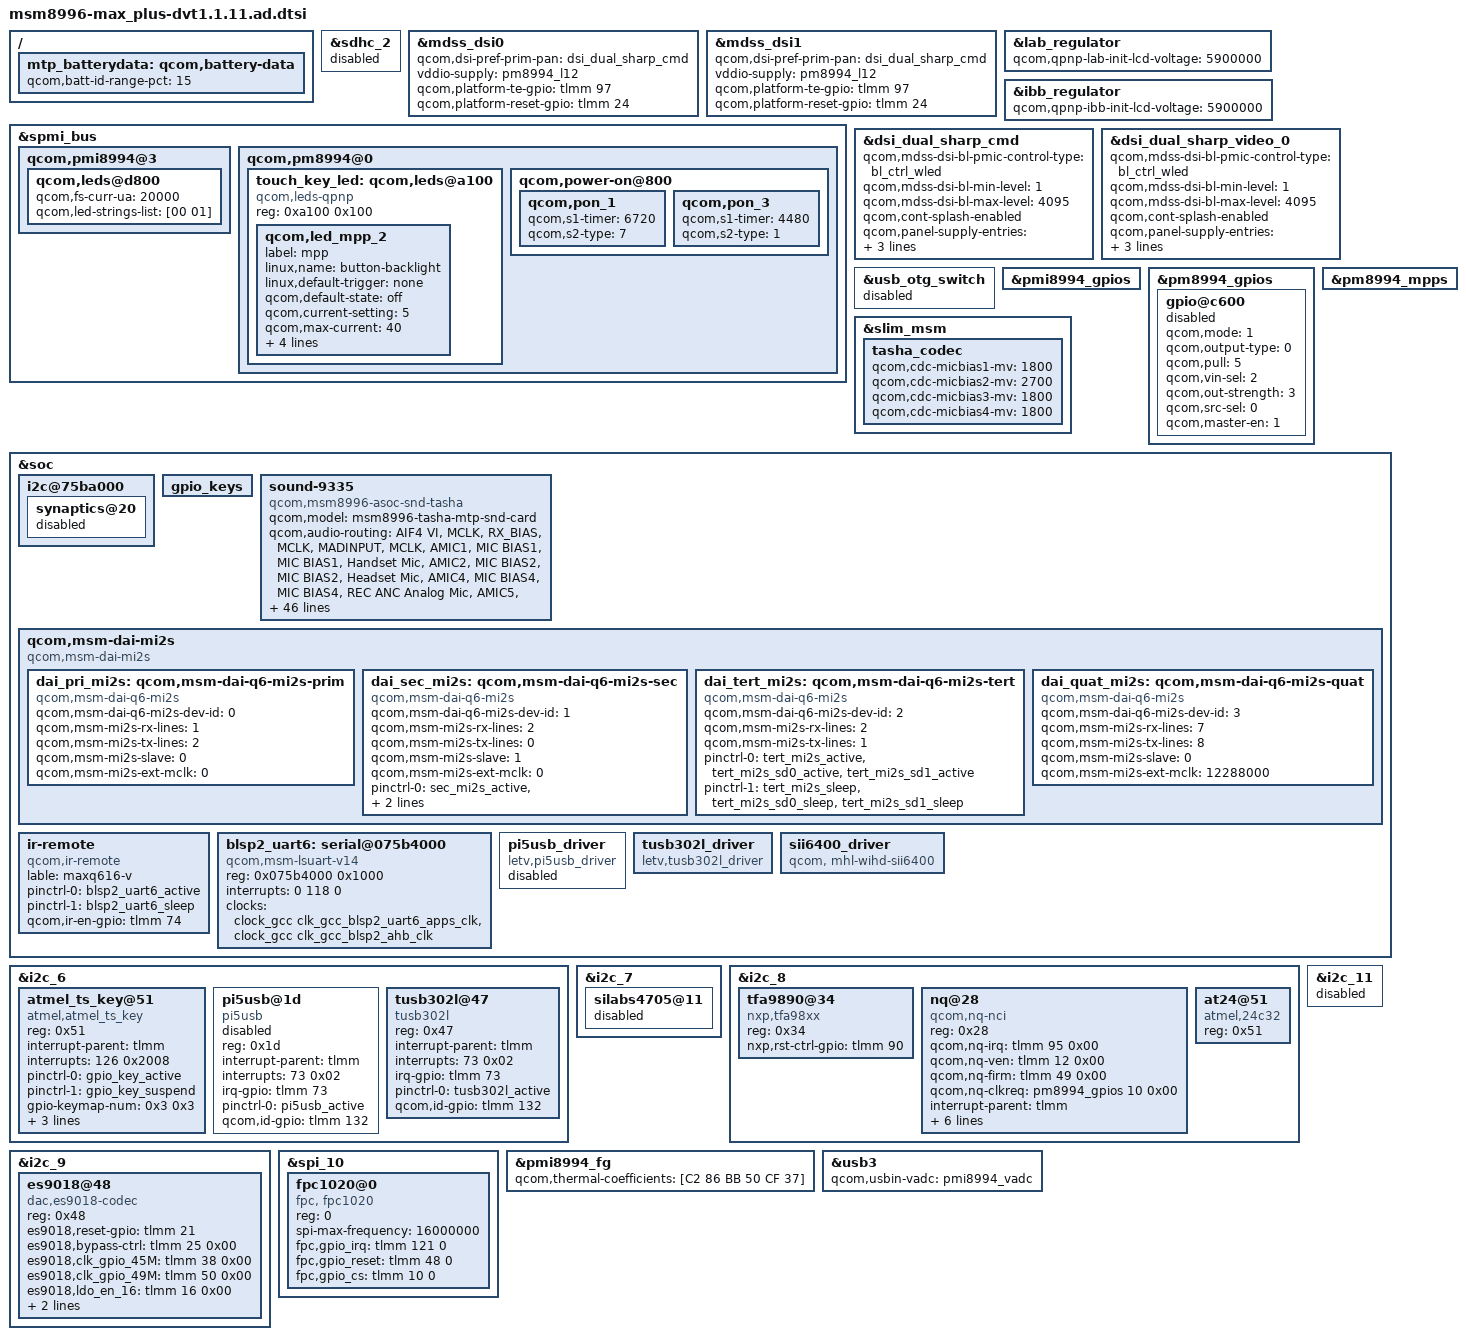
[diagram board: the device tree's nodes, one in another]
/* Copyright (c) 2015, The Linux Foundation. All rights reserved.
 *
 * This program is free software; you can redistribute it and/or modify
 * it under the terms of the GNU General Public License version 2 and
 * only version 2 as published by the Free Software Foundation.
 *
 * This program is distributed in the hope that it will be useful,
 * but WITHOUT ANY WARRANTY; without even the implied warranty of
 * MERCHANTABILITY or FITNESS FOR A PARTICULAR PURPOSE.  See the
 * GNU General Public License for more details.
 */

#include "msm8996-mtp-le-common.dtsi"
#include "msm8996-pinctrl-max_plus.dtsi"
#include "msm8996-le-common.dtsi"
#include "dsi-panel-sharp-dualmipi-cmd.dtsi"
#include "dsi-panel-sharp-dualmipi-video.dtsi"
#include "letv-tp-atmel_mxt_ts.dtsi"
#include "msm8996-camera-sensor-maxplus-dvt1.1.dtsi"

&sdhc_2 {
	status = "disabled";
};

&mdss_dsi0 {
	qcom,dsi-pref-prim-pan = <&dsi_dual_sharp_cmd>;
	vddio-supply = <&pm8994_l12>;
	qcom,platform-te-gpio = <&tlmm 97 0>;
	qcom,platform-reset-gpio = <&tlmm 24 0>;
	/delete-property/ qcom,platform-bklight-en-gpio;
};

&mdss_dsi1 {
	qcom,dsi-pref-prim-pan = <&dsi_dual_sharp_cmd>;
	vddio-supply = <&pm8994_l12>;
	qcom,platform-te-gpio = <&tlmm 97 0>;
	qcom,platform-reset-gpio = <&tlmm 24 0>;
	/delete-property/ qcom,platform-bklight-en-gpio;
};

&lab_regulator {
	qcom,qpnp-lab-init-lcd-voltage = <5900000>;
};

&ibb_regulator {
	qcom,qpnp-ibb-init-lcd-voltage = <5900000>;
};

&spmi_bus {
	qcom,pmi8994@3 {
		qcom,leds@d800 {
			qcom,fs-curr-ua = <20000>;
			qcom,led-strings-list = [00 01];
		};
	};

	qcom,pm8994@0 {
		/* configure pm8994 MPP2 as back-light of touch key */
		touch_key_led: qcom,leds@a100 {
			compatible = "qcom,leds-qpnp";
			reg = <0xa100 0x100>;
			status = "okay";

			qcom,led_mpp_2 {
				label = "mpp";
				linux,name = "button-backlight";
				linux,default-trigger = "none";
				qcom,default-state = "off";
				qcom,current-setting = <5>;
				qcom,max-current = <40>;
				qcom,id = <6>;
				qcom,source-sel = <1>;
				qcom,mode-ctrl = <0x60>; /* current sink mode */
				qcom,mode = "manual";
			};
		};

		/*long press power key hardreset,  long press power+vol_donw into ramdump mode*/
		qcom,power-on@800 {
			qcom,pon_1 {
				qcom,s1-timer = <6720>;
				qcom,s2-type = <7>;
			};

			qcom,pon_3 {
				qcom,s1-timer = <4480>;
				qcom,s2-type = <1>;
			};
		};
	};
};

&dsi_dual_sharp_cmd {
	qcom,mdss-dsi-bl-pmic-control-type = "bl_ctrl_wled";
	qcom,mdss-dsi-bl-min-level = <1>;
	qcom,mdss-dsi-bl-max-level = <4095>;
	qcom,cont-splash-enabled;
	qcom,panel-supply-entries = <&dsi_panel_pwr_supply>;

	qcom,mdss-dsi-panel-timings-phy-v2 = [22 1e 07 08 04 03 04 a0
		22 1e 07 08 04 03 04 a0
		22 1e 07 08 04 03 04 a0
		22 1e 07 08 04 03 04 a0
		23 17 06 08 05 03 04 a0];
};

&dsi_dual_sharp_video_0 {
	qcom,mdss-dsi-bl-pmic-control-type = "bl_ctrl_wled";
	qcom,mdss-dsi-bl-min-level = <1>;
	qcom,mdss-dsi-bl-max-level = <4095>;
	qcom,cont-splash-enabled;
	qcom,panel-supply-entries = <&dsi_panel_pwr_supply>;

	qcom,mdss-dsi-panel-timings-phy-v2 = [22 1e 07 08 04 03 04 a0
		22 1e 07 08 04 03 04 a0
		22 1e 07 08 04 03 04 a0
		22 1e 07 08 04 03 04 a0
		23 17 06 08 05 03 04 a0];
};

&usb_otg_switch {
	status = "disabled";
};

&pmi8994_gpios {
	/delete-node/ gpio@c100; /* PMI8994 GPIO 2 */
	/delete-node/ gpio@c200; /* PMI8994 GPIO 3 */
};

&pm8994_gpios {
	gpio@c600 { /* GPIO 7 - NFC DWL REQ */
		qcom,mode = <1>;
		qcom,output-type = <0>;
		qcom,pull = <5>;
		qcom,vin-sel = <2>;
		qcom,out-strength = <3>;
		qcom,src-sel = <0>;
		qcom,master-en = <1>;
		status = "disabled";
	};
};

&pm8994_mpps {
	/* Remove pm8994 MPP2 reference function, because it is
	configured as back-light of touch key */
	/delete-node/ mpp@a100; /* MPP 2 */
};

&slim_msm {
	tasha_codec {
		qcom,cdc-micbias1-mv = <1800>;
		qcom,cdc-micbias2-mv = <2700>;
		qcom,cdc-micbias3-mv = <1800>;
		qcom,cdc-micbias4-mv = <1800>;

		/delete-node/ wsa881x@20170211;
		/delete-node/ wsa881x@20170212;
		/delete-node/ wsa881x@21170213;
		/delete-node/ wsa881x@21170214;
	};
};

&soc {
	i2c@75ba000 {
		synaptics@20 {
			status = "disabled";
		};
	};

	/delete-node/ gen-vkeys;

	gpio_keys {
		/delete-node/ cam_focus;
	};

	/delete-node/ flash_led;

	sound-9335 {
                compatible = "qcom,msm8996-asoc-snd-tasha";
		qcom,model = "msm8996-tasha-mtp-snd-card";

		qcom,audio-routing =
			"AIF4 VI", "MCLK",
			"RX_BIAS", "MCLK",
			"MADINPUT", "MCLK",
			"AMIC1", "MIC BIAS1",
			"MIC BIAS1", "Handset Mic",
			"AMIC2", "MIC BIAS2",
			"MIC BIAS2", "Headset Mic",
			"AMIC4", "MIC BIAS4",
			"MIC BIAS4", "REC ANC Analog Mic",
			"AMIC5", "MIC BIAS3",
			"MIC BIAS3", "ANC Analog Mic",
			"AMIC6", "MIC BIAS1",
			"MIC BIAS1", "Analog Mic6";

                asoc-platform = <&pcm0>, <&pcm1>, <&pcm2>, <&voip>, <&voice>,
                                <&loopback>, <&compress>, <&hostless>,
                                <&afe>, <&lsm>, <&routing>, <&cpe>,
                                <&compr>, <&pcmnoirq>, <&cpe3>;
                asoc-platform-names = "msm-pcm-dsp.0", "msm-pcm-dsp.1", "msm-pcm-dsp.2",
                                "msm-voip-dsp", "msm-pcm-voice", "msm-pcm-loopback",
                                "msm-compress-dsp", "msm-pcm-hostless", "msm-pcm-afe",
                                "msm-lsm-client", "msm-pcm-routing", "msm-cpe-lsm",
                                "msm-compr-dsp", "msm-pcm-dsp-noirq",
                                "msm-cpe-lsm.3";
		asoc-cpu = <&dai_pri_auxpcm>, <&dai_sec_auxpcm>, <&dai_hdmi>,
				<&dai_pri_mi2s>, <&dai_sec_mi2s>,
				<&dai_tert_mi2s>, <&dai_quat_mi2s>,
				<&sb_0_rx>, <&sb_0_tx>, <&sb_1_rx>, <&sb_1_tx>,
				<&sb_2_rx>, <&sb_2_tx>, <&sb_3_rx>, <&sb_3_tx>,
				<&sb_4_rx>, <&sb_4_tx>, <&sb_5_tx>, <&afe_pcm_rx>,
				<&afe_pcm_tx>, <&afe_proxy_rx>, <&afe_proxy_tx>,
				<&incall_record_rx>, <&incall_record_tx>,
				<&incall_music_rx>, <&incall_music2_rx>,
				<&sb_5_rx>, <&sb_6_rx>;
		asoc-cpu-names = "msm-dai-q6-auxpcm.1", "msm-dai-q6-auxpcm.2",
				"msm-dai-q6-hdmi.8",
				"msm-dai-q6-mi2s.0", "msm-dai-q6-mi2s.1",
				"msm-dai-q6-mi2s.2", "msm-dai-q6-mi2s.3",
				"msm-dai-q6-dev.16384", "msm-dai-q6-dev.16385",
				"msm-dai-q6-dev.16386", "msm-dai-q6-dev.16387",
				"msm-dai-q6-dev.16388", "msm-dai-q6-dev.16389",
				"msm-dai-q6-dev.16390", "msm-dai-q6-dev.16391",
				"msm-dai-q6-dev.16392", "msm-dai-q6-dev.16393",
				"msm-dai-q6-dev.16395", "msm-dai-q6-dev.224",
				"msm-dai-q6-dev.225", "msm-dai-q6-dev.241",
				"msm-dai-q6-dev.240", "msm-dai-q6-dev.32771",
				"msm-dai-q6-dev.32772", "msm-dai-q6-dev.32773",
				"msm-dai-q6-dev.32770", "msm-dai-q6-dev.16394",
				"msm-dai-q6-dev.16396";

		qcom,hdmi-audio-rx;
		letv,hifi-audio;
		letv,smartpa-audio;
		letv,hph_irq_detect = <1>;
		asoc-codec = <&stub_codec>, <&hdmi_audio>;
		asoc-codec-names = "msm-stub-codec.1", "msm-hdmi-audio-codec-rx";
		/delete-property/ qcom,hph-en1-gpio;
		/delete-property/ qcom,hph-en0-gpio;
		/delete-property/ qcom,us-euro-gpios;
		qcom,wsa-max-devs = <0>;
		qcom,wsa-devs = <0>;
		qcom,wsa-aux-dev-prefix = <0>;
	};

	qcom,msm-dai-mi2s {
		compatible = "qcom,msm-dai-mi2s";
		dai_pri_mi2s: qcom,msm-dai-q6-mi2s-prim {
			compatible = "qcom,msm-dai-q6-mi2s";
			qcom,msm-dai-q6-mi2s-dev-id = <0>;
			qcom,msm-mi2s-rx-lines = <1>; /* SD0 (1 << 0) */
			qcom,msm-mi2s-tx-lines = <2>; /* SD1 (1 << 1) */
			qcom,msm-mi2s-slave = <0>;
			qcom,msm-mi2s-ext-mclk = <0>;
			/*pinctrl-names = "default", "idle";
			pinctrl-0 = <&pri_mi2s_active &pri_mi2s_mclk_active &pri_mi2s_sd0_active &pri_mi2s_sd1_active>;
			pinctrl-1 = <&pri_mi2s_sleep &pri_mi2s_mclk_sleep &pri_mi2s_sd0_sleep &pri_mi2s_sd1_sleep>;*/
		};
	};

	qcom,msm-dai-mi2s {
		compatible = "qcom,msm-dai-mi2s";
		dai_sec_mi2s: qcom,msm-dai-q6-mi2s-sec {
			compatible = "qcom,msm-dai-q6-mi2s";
			qcom,msm-dai-q6-mi2s-dev-id = <1>;
			qcom,msm-mi2s-rx-lines = <2>; /* SD0 (1 << 0) | SD1 (1 << 1) */
			qcom,msm-mi2s-tx-lines = <0>; /* None */
			qcom,msm-mi2s-slave = <1>;
			qcom,msm-mi2s-ext-mclk = <0>;
			pinctrl-names = "default", "idle";
			/*pinctrl-0 = <&sec_mi2s_active &sec_mi2s_mclk_active &sec_mi2s_sd0_active &sec_mi2s_sd1_active>;
			pinctrl-1 = <&sec_mi2s_sleep &sec_mi2s_mclk_sleep &sec_mi2s_sd0_sleep &sec_mi2s_sd1_sleep>;*/
			pinctrl-0 = <&sec_mi2s_active &sec_mi2s_sd1_active>;
			pinctrl-1 = <&sec_mi2s_sleep &sec_mi2s_sd1_sleep>;
		};
	};

	qcom,msm-dai-mi2s {
		compatible = "qcom,msm-dai-mi2s";
		dai_tert_mi2s: qcom,msm-dai-q6-mi2s-tert {
			compatible = "qcom,msm-dai-q6-mi2s";
			qcom,msm-dai-q6-mi2s-dev-id = <2>;
			qcom,msm-mi2s-rx-lines = <2>;
			qcom,msm-mi2s-tx-lines = <1>;
			pinctrl-names = "default", "sleep";
			pinctrl-0 = <&tert_mi2s_active &tert_mi2s_sd0_active &tert_mi2s_sd1_active>;
			pinctrl-1 = <&tert_mi2s_sleep &tert_mi2s_sd0_sleep &tert_mi2s_sd1_sleep>;
		};
	};

	qcom,msm-dai-mi2s {
		compatible = "qcom,msm-dai-mi2s";
		dai_quat_mi2s: qcom,msm-dai-q6-mi2s-quat {
			compatible = "qcom,msm-dai-q6-mi2s";
			qcom,msm-dai-q6-mi2s-dev-id = <3>;
			qcom,msm-mi2s-rx-lines = <7>; /* SD0 (1 << 0) | SD1 (1 << 1) | SD2 (1 << 2) */
			qcom,msm-mi2s-tx-lines = <8>; /* SD2 (1 << 3) */
			qcom,msm-mi2s-slave = <0>;
			qcom,msm-mi2s-ext-mclk = <12288000>;
			/*pinctrl-names = "default", "idle";
			pinctrl-0 = <&quat_mi2s_active &quat_mi2s_mclk_active &quat_mi2s_sd0_active &quat_mi2s_sd1_active &quat_mi2s_sd2_active &quat_mi2s_sd3_active>;
			pinctrl-1 = <&quat_mi2s_sleep &quat_mi2s_mclk_sleep &quat_mi2s_sd0_sleep &quat_mi2s_sd1_sleep &quat_mi2s_sd2_sleep &quat_mi2s_sd3_sleep>;*/
		};
	};

	ir-remote {
		compatible = "qcom,ir-remote";
		lable = "maxq616-v";
		pinctrl-names = "ir_active", "ir_sleep";
		pinctrl-0 = <&blsp2_uart6_active>;
		pinctrl-1 = <&blsp2_uart6_sleep>;
		qcom,ir-en-gpio = <&tlmm 74 0>;
	};

	blsp2_uart6: serial@075b4000 {
		compatible = "qcom,msm-lsuart-v14";
		reg = <0x075b4000 0x1000>;
		interrupts = <0 118 0>;
		status = "disabled";

		clock-names = "core_clk", "iface_clk";
		clocks = <&clock_gcc clk_gcc_blsp2_uart6_apps_clk>,
			<&clock_gcc clk_gcc_blsp2_ahb_clk>;
	};

	pi5usb_driver {
		compatible = "letv,pi5usb_driver";
		status = "disabled";
	};

	tusb302l_driver {
		compatible = "letv,tusb302l_driver";
		status = "ok";
	};

	sii6400_driver {
		compatible = "qcom, mhl-wihd-sii6400";
		status = "ok";
	};
};

&blsp2_uart6 {
	status = "ok";
};

&i2c_6 {
	/delete-node/ at24@51;
	atmel_ts_key@51 {
		status = "ok";
		compatible = "atmel,atmel_ts_key";
		reg = <0x51>;
		interrupt-parent = <&tlmm>;
		interrupts = <126 0x2008>;
		pinctrl-names = "tlmm_gpio_key_active","tlmm_gpio_key_suspend";
		pinctrl-0 = <&gpio_key_active>;
		pinctrl-1 = <&gpio_key_suspend>;
		gpio-keymap-num = <0x3 0x3>;
		gpio-keymap_0 = <158 580 172>;
		gpio-keymap_1 = <158 31 30>;
		atmel,fw_name= "Letv_max1_tk_58_0A_1.3_0A.fw";
	};

	pi5usb@1d {
		status = "disabled";
		compatible = "pi5usb";
		reg =<0x1d>;
		interrupt-parent = <&tlmm>;
		interrupts = <73 0x02>;
		irq-gpio = <&tlmm 73 0x00>;
		pinctrl-names = "pi5usb_active";
		pinctrl-0 = <&pi5usb_active>;
		qcom,id-gpio = <&tlmm 132 0>;
	};

	tusb302l@47 {
		status = "ok";
		compatible = "tusb302l";
		reg =<0x47>;
		interrupt-parent = <&tlmm>;
		interrupts = <73 0x02>;
		irq-gpio = <&tlmm 73 0x00>;
		pinctrl-names = "tusb302l_active";
		pinctrl-0 = <&tusb302l_active>;
		qcom,id-gpio = <&tlmm 132 0>;
	};
};

&i2c_7 {
	silabs4705@11 { /* SiLabs FM chip, slave id 0x11*/
		status = "disabled";
	};
};

&i2c_8 {
	tfa9890@34 { /* tfa9890 smartpa device */
		compatible = "nxp,tfa98xx";
		reg = <0x34>;
		nxp,rst-ctrl-gpio = <&tlmm 90 0x00>;
	};

	nq@28 {
		compatible = "qcom,nq-nci";
		reg = <0x28>;
		qcom,nq-irq = <&tlmm 95 0x00>;
		qcom,nq-ven = <&tlmm 12 0x00>;
		qcom,nq-firm = <&tlmm 49 0x00>;
		qcom,nq-clkreq = <&pm8994_gpios 10 0x00>;
		interrupt-parent = <&tlmm>;
		qcom,clk-src = "BBCLK2";
		interrupts = <95 0>;
		interrupt-names = "nfc_irq";
		pinctrl-names = "nfc_active", "nfc_suspend";
		pinctrl-0 = <&nfc_int_active &nfc_disable_active>;
		pinctrl-1 = <&nfc_int_suspend &nfc_disable_suspend>;
		clocks = <&clock_gcc clk_bb_clk2_pin>;
		clock-names = "ref_clk";
	};
	at24@51 {
		compatible = "atmel,24c32";
		reg = <0x51>;
	};
};

&i2c_9 {
	es9018@48 { /* es9018 hifi device */
		compatible = "dac,es9018-codec";
		reg = <0x48>;
		es9018,reset-gpio = <&tlmm 21 0x00>;
		es9018,bypass-ctrl = <&tlmm 25 0x00>;
		es9018,clk_gpio_45M = <&tlmm 38 0x00>;
		es9018,clk_gpio_49M = <&tlmm 50 0x00>;
		es9018,ldo_en_16 = <&tlmm 16 0x00>;
		es9018,ldo_en_40 = <&tlmm 40 0x00>;
		es9018,ldo_en_84 = <&tlmm 84 0x00>;
	};
};

&spi_10 {
	status = "ok";
	fpc1020@0 {
		compatible = "fpc, fpc1020";
		reg = <0>;
		spi-max-frequency = <16000000>;
		fpc,gpio_irq = <&tlmm 121 0>;
		fpc,gpio_reset = <&tlmm 48 0>;
		fpc,gpio_cs = <&tlmm 10 0>;
	};
};

/{
	mtp_batterydata: qcom,battery-data {
		qcom,batt-id-range-pct = <15>;
		#include "batterydata-max-plus-3395mah.dtsi"
	};
};

&pmi8994_fg {
	qcom,thermal-coefficients = [C2 86 BB 50 CF 37];
};
/*
&pcie1 {
    status = "disabled";
};

&spi_11 {
	status = "ok";
	sii6400@0 {
		compatible = "qcom, mhl-wihd-sii6400";
		reg = <0>;
		interrupt-parent = <&tlmm>;
		interrupts = <123 0>;
		spi-max-frequency = <35000000>;
		intr-gpio = <&tlmm 123 0>;
		hdmi-det = <&tlmm 79 0>;
		rst-gpio = <&tlmm 14 0>;
		pwr-gpio = <&tlmm 94 0>;
		mhl-sel1-gpio = <&tlmm 30 0>;
		qcom,hdmi-tx-map = <&mdss_hdmi_tx>;
	};
};

&pmi8994_charger {
	qcom,mhl-wihd = <1>;
};
*/

&i2c_11{
	status = "disabled";
};

&usb3 {
	qcom,usbin-vadc = <&pmi8994_vadc>;
};
